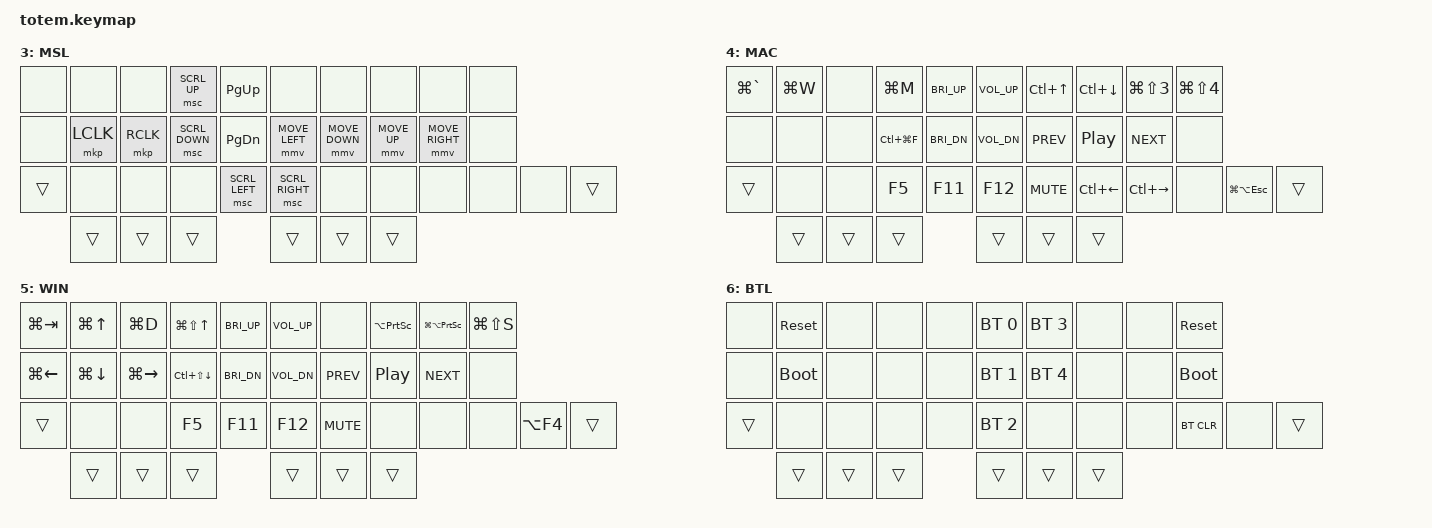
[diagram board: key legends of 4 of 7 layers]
/*
 * Copyright (c) 2020 The ZMK Contributors
 *
 * SPDX-License-Identifier: MIT
 */

#define ZMK_POINTING_DEFAULT_MOVE_VAL 3200
#define ZMK_POINTING_DEFAULT_SCROLL_VAL 720

#include <behaviors.dtsi>
#include <dt-bindings/zmk/keys.h>
#include <dt-bindings/zmk/bt.h>
#include <dt-bindings/zmk/pointing.h>

#define HRML(k1, k2, k3, k4) &ht LSHFT k1 &ht LALT k2 &ht LCTRL k3 &ht LGUI k4
#define HRMR(k1, k2, k3, k4) &ht RGUI k1 &ht RCTRL k2 &ht RALT k3 &ht RSHIFT k4

/ {
    behaviors {
        ht: hold_tap {
            compatible = "zmk,behavior-hold-tap";
            #binding-cells = <2>;
            flavor = "tap-preferred";
            tapping-term-ms = <220>;
            quick-tap-ms = <150>;
            require-prior-idle-ms = <100>;
            bindings = <&kp>, <&kp>;
        };
    };

    combos {
        compatible = "zmk,combos";

        combo_esc {
            timeout-ms = <50>;
            key-positions = <0 1>;
            bindings = <&kp ESC>;
        };
    };

    conditional_layers {
        compatible = "zmk,conditional-layers";

        mac_layer {
            if-layers = <1 3>;
            then-layer = <4>;
        };

        win_layer {
            if-layers = <1 2>;
            then-layer = <5>;
        };

        bt_and_bl {
            if-layers = <1 2 3>;
            then-layer = <6>;
        };
    };

    keymap {
        compatible = "zmk,keymap";

        default_layer {
            display-name = "TOP";
            bindings = <
                // Row 1: L0 L1 L2 L3 L4                         R0 R1 R2 R3 R4
                &kp Q                    &kp W                    &kp E                    &kp R                    &kp T                    &mt RC(LS(COMMA)) Y    &kp U                    &kp I                    &kp O                    &kp P
                // Row 2: L0 L1 L2 L3 L4                         R0 R1 R2 R3 R4
                HRML(A, S, D, F)         &kp G                    &kp H                    HRMR(J, K, L, SQT)
                // Row 3: LO L0 L1 L2 L3 L4                      R0 R1 R2 R3 R4 RO
                &kp ESC                  &kp Z                    &kp X                    &kp C                    &kp V                    &kp B                    &kp N                    &kp M                    &kp COMMA                &kp DOT                  &kp FSLH                 &kp PSCRN
                // Thumb:    LT0                                      LT1                      LT2                          RT0                           RT1                      RT2
                                                     &kp PG_DN                &lt 3 TAB                 &lt 2 BSPC                    &mt RC(RS(RALT)) ENTER      &lt 1 SPACE                &kp PG_UP
            >;
        };

        right_layer {
            display-name = "NUM";
            bindings = <
                // Row 1: L0 L1 L2 L3 L4                         R0 R1 R2 R3 R4
                &none                    &kp N1                   &kp N2                   &kp N3                   &kp PG_UP                &kp HOME                 &mkp LCLK                &mkp RCLK                &none                    &none
                // Row 2: L0 L1 L2 L3 L4                         R0 R1 R2 R3 R4
                HRML(PSCRN, N4, N5, N6)  &kp PG_DN                &kp LEFT                 HRMR(DOWN, UP, RIGHT, NUHS)
                // Row 3: LO L0 L1 L2 L3 L4                      R0 R1 R2 R3 R4 RO
                &trans                   &none                    &kp N7                   &kp N8                   &kp N9                   &kp N0                   &kp END                  &none                    &none                    &none                    &none                    &trans
                // Thumb:    LT0                                      LT1                      LT2                          RT0                           RT1                      RT2
                                                     &trans                  &trans                   &trans                       &trans                       &trans                    &trans
            >;
        };

        left_layer {
            display-name = "SYM";
            bindings = <
                // Row 1: L0 L1 L2 L3 L4                         R0 R1 R2 R3 R4
                &kp EXCL                 &kp AT                   &kp HASH                 &kp DLLR                 &kp PRCNT                &kp ASTRK                &kp MINUS                &kp UNDER                &kp EQUAL                &kp BSLH
                // Row 2: L0 L1 L2 L3 L4                         R0 R1 R2 R3 R4
                HRML(F13, F14, F15, AMPS) &kp CARET              &kp LBKT                 HRMR(LPAR, LBRC, COLON, TILDE)
                // Row 3: LO L0 L1 L2 L3 L4                      R0 R1 R2 R3 R4 RO
                &trans                   &none                    &none                    &none                    &kp GRAVE                &kp PLUS                 &kp RBKT                 &kp RPAR                 &kp RBRC                 &kp SEMI                 &kp PIPE                 &trans
                // Thumb:    LT0                                      LT1                      LT2                          RT0                           RT1                      RT2
                                                     &trans                  &trans                   &trans                       &trans                       &trans                    &trans
            >;
        };

        mouse_layer {
            display-name = "MSL";
            bindings = <
                // Row 1: L0 L1 L2 L3 L4                         R0 R1 R2 R3 R4
                &none                    &none                    &none                    &msc SCRL_UP             &kp PG_UP                &none                    &none                    &none                    &none                    &none
                // Row 2: L0 L1 L2 L3 L4                         R0 R1 R2 R3 R4
                &none                    &mkp LCLK                &mkp RCLK                &msc SCRL_DOWN           &kp PG_DN                &mmv MOVE_LEFT           &mmv MOVE_DOWN           &mmv MOVE_UP             &mmv MOVE_RIGHT          &none
                // Row 3: LO L0 L1 L2 L3 L4                      R0 R1 R2 R3 R4 RO
                &trans                   &none                    &none                    &none                    &msc SCRL_LEFT           &msc SCRL_RIGHT          &none                    &none                    &none                    &none                    &none                    &trans
                // Thumb:    LT0                                      LT1                      LT2                          RT0                           RT1                      RT2
                                                     &trans                  &trans                   &trans                       &trans                       &trans                    &trans
            >;
        };

        mac_layer {
            display-name = "MAC";
            bindings = <
                // Row 1: L0 L1 L2 L3 L4                         R0 R1 R2 R3 R4
                &kp LG(GRAVE)            &kp LG(W)                &none                    &kp LG(M)                &kp C_BRI_UP             &kp C_VOL_UP             &kp LC(UP)               &kp LC(DOWN)             &kp LG(LS(N3))           &kp LG(LS(N4))
                // Row 2: L0 L1 L2 L3 L4                         R0 R1 R2 R3 R4
                &none                    &none                    &none                    &kp LC(LG(F))            &kp C_BRI_DN             &kp C_VOL_DN             &kp C_PREV               &kp C_PP                 &kp C_NEXT               &none
                // Row 3: LO L0 L1 L2 L3 L4                      R0 R1 R2 R3 R4 RO
                &trans                   &none                    &none                    &kp F5                   &kp F11                  &kp F12                  &kp C_MUTE               &kp LC(LEFT)             &kp LC(RIGHT)            &none                    &kp LG(LA(ESC))          &trans
                // Thumb:    LT0                                      LT1                      LT2                          RT0                           RT1                      RT2
                                                     &trans                  &trans                   &trans                       &trans                       &trans                    &trans
            >;
        };

        win_layer {
            display-name = "WIN";
            bindings = <
                // Row 1: L0 L1 L2 L3 L4                         R0 R1 R2 R3 R4
                &kp LG(TAB)              &kp LG(UP)               &kp LG(D)                &kp LG(LS(UP))           &kp C_BRI_UP             &kp C_VOL_UP             &none                    &kp LA(PSCRN)            &kp LG(LA(PSCRN))        &kp LG(LS(S))
                // Row 2: L0 L1 L2 L3 L4                         R0 R1 R2 R3 R4
                &kp LG(LEFT)             &kp LG(DOWN)             &kp LG(RIGHT)            &kp LC(LS(DOWN))         &kp C_BRI_DN             &kp C_VOL_DN             &kp C_PREV               &kp C_PP                 &kp C_NEXT               &none
                // Row 3: LO L0 L1 L2 L3 L4                      R0 R1 R2 R3 R4 RO
                &trans                   &none                    &none                    &kp F5                   &kp F11                  &kp F12                  &kp C_MUTE               &none                    &none                    &none                    &kp LA(F4)               &trans
                // Thumb:    LT0                                      LT1                      LT2                          RT0                           RT1                      RT2
                                                     &trans                  &trans                   &trans                       &trans                       &trans                    &trans
            >;
        };

        bt_and_bl {
            display-name = "BTL";
            bindings = <
                // Row 1: L0 L1 L2 L3 L4                         R0 R1 R2 R3 R4
                &none                    &sys_reset               &none                    &none                    &none                    &bt BT_SEL 0             &bt BT_SEL 3             &none                    &none                    &sys_reset
                // Row 2: L0 L1 L2 L3 L4                         R0 R1 R2 R3 R4
                &none                    &bootloader              &none                    &none                    &none                    &bt BT_SEL 1             &bt BT_SEL 4             &none                    &none                    &bootloader
                // Row 3: LO L0 L1 L2 L3 L4                      R0 R1 R2 R3 R4 RO
                &trans                   &none                    &none                    &none                    &none                    &bt BT_SEL 2             &none                    &none                    &none                    &bt BT_CLR               &none                    &trans
                // Thumb:    LT0                                      LT1                      LT2                          RT0                           RT1                      RT2
                                                     &trans                  &trans                   &trans                       &trans                       &trans                    &trans
            >;
        };
    };
};
